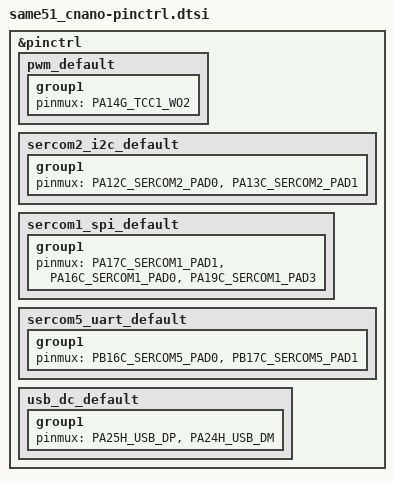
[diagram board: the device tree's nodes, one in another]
/*
 * Copyright (c) 2022, Gerson Fernando Budke <nandojve@gmail.com>
 * SPDX-License-Identifier: Apache-2.0
 */

#include <dt-bindings/pinctrl/same51j-pinctrl.h>

&pinctrl {
	pwm_default: pwm_default {
		group1 {
			pinmux = <PA14G_TCC1_WO2>;
		};
	};

	sercom2_i2c_default: sercom2_i2c_default {
		group1 {
			pinmux = <PA12C_SERCOM2_PAD0>,
				 <PA13C_SERCOM2_PAD1>;
		};
	};

	sercom1_spi_default: sercom1_spi_default {
		group1 {
			pinmux = <PA17C_SERCOM1_PAD1>,
				 <PA16C_SERCOM1_PAD0>,
				 <PA19C_SERCOM1_PAD3>;
		};
	};

	sercom5_uart_default: sercom5_uart_default {
		group1 {
			pinmux = <PB16C_SERCOM5_PAD0>,
				 <PB17C_SERCOM5_PAD1>;
		};
	};

	usb_dc_default: usb_dc_default {
		group1 {
			pinmux = <PA25H_USB_DP>,
				 <PA24H_USB_DM>;
		};
	};
};
